# TEST register map
Vendor: TEST; Series: TEST; File version: 6
CPU: Xtensa LX6 r0p0, little endian, no MPU, FPU, 3 interrupt priority bits
Address unit: 32 bits
Registers are 32-bit, write-only, reset 0x0 unless marked. A register's access mark holds for its fields unless they carry their own. Offsets are from the block's base; lines under a group give offsets from that group; [hi:lo] are bit positions; {n}, {i} and the like mark numbered series; 'fields as' and 'values as' point back to an identical list; <NAME> marks a mode.

## Memory map
0x3FF56000 RMT size 0xF8 — Remote Control Peripheral

## Interrupts
47 RMT

## RMT — Remote Control Peripheral
Base 0x3FF56000
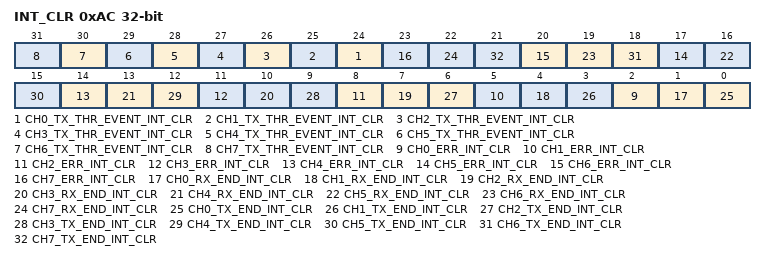
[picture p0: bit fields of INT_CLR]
0xAC INT_CLR
  [n+24] CH{n}_TX_THR_EVENT_INT_CLR (n=0..7) — Set this bit to clear the rmt_ch{n}_tx_thr_event_int_raw interrupt.
  [3n+2] CH{n}_ERR_INT_CLR (n=0..7) — Set this bit to clear the rmt_ch{n}_err_int_raw.
  [3n+1] CH{n}_RX_END_INT_CLR (n=0..7) — Set this bit to clear the rmt_ch{n}_tx_end_int_raw.
  [3n] CH{n}_TX_END_INT_CLR (n=0..7) — Set this bit to clear the rmt_ch{n}_rx_end_int_raw..

## Licence text in the file
TEST
